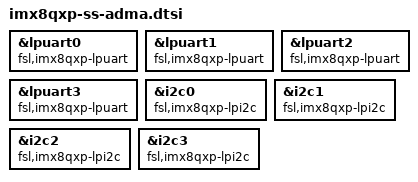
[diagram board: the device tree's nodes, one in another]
// SPDX-License-Identifier: GPL-2.0+
/*
 * Copyright 2018-2020 NXP
 *	Dong Aisheng <aisheng.dong@nxp.com>
 */

&lpuart0 {
	compatible = "fsl,imx8qxp-lpuart", "fsl,imx7ulp-lpuart";
};

&lpuart1 {
	compatible = "fsl,imx8qxp-lpuart", "fsl,imx7ulp-lpuart";
};

&lpuart2 {
	compatible = "fsl,imx8qxp-lpuart", "fsl,imx7ulp-lpuart";
};

&lpuart3 {
	compatible = "fsl,imx8qxp-lpuart", "fsl,imx7ulp-lpuart";
};

&i2c0 {
	compatible = "fsl,imx8qxp-lpi2c", "fsl,imx7ulp-lpi2c";
};

&i2c1 {
	compatible = "fsl,imx8qxp-lpi2c", "fsl,imx7ulp-lpi2c";
};

&i2c2 {
	compatible = "fsl,imx8qxp-lpi2c", "fsl,imx7ulp-lpi2c";
};

&i2c3 {
	compatible = "fsl,imx8qxp-lpi2c", "fsl,imx7ulp-lpi2c";
};
